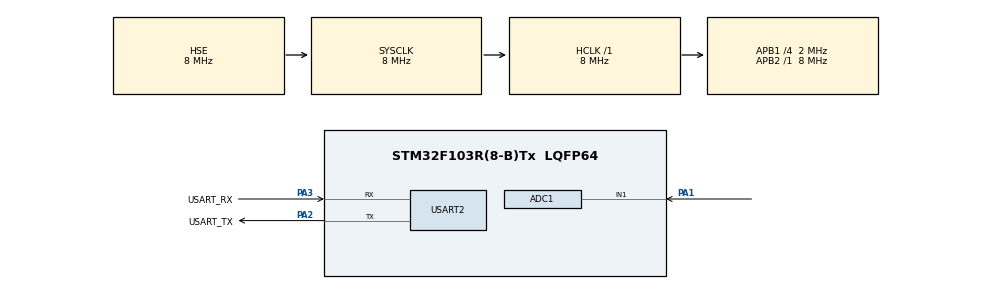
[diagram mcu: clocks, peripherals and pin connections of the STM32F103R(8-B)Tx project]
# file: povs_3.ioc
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ADC1.Channel-0\#ChannelRegularConversion=ADC_CHANNEL_1
ADC1.ContinuousConvMode=ENABLE
ADC1.NbrOfConversion=1
ADC1.NbrOfConversionFlag=1
ADC1.Rank-0\#ChannelRegularConversion=1
ADC1.SamplingTime-0\#ChannelRegularConversion=ADC_SAMPLETIME_239CYCLES_5
ADC1.master=1
Dma.ADC1.0.Direction=DMA_PERIPH_TO_MEMORY
Dma.ADC1.0.Instance=DMA1_Channel1
Dma.ADC1.0.MemDataAlignment=DMA_MDATAALIGN_WORD
Dma.ADC1.0.MemInc=DMA_MINC_ENABLE
Dma.ADC1.0.Mode=DMA_CIRCULAR
Dma.ADC1.0.PeriphDataAlignment=DMA_PDATAALIGN_WORD
Dma.ADC1.0.PeriphInc=DMA_PINC_DISABLE
Dma.ADC1.0.Priority=DMA_PRIORITY_LOW
Dma.Request0=ADC1
Mcu.Family=STM32F1
Mcu.Name=STM32F103R(8-B)Tx
Mcu.Package=LQFP64
NVIC.DMA1_Channel1_IRQn=true\:0\:0\:false\:false\:true\:false\:true\:true
NVIC.PriorityGroup=NVIC_PRIORITYGROUP_4
NVIC.TIM3_IRQn=true\:0\:0\:false\:false\:true\:true\:true\:true
NVIC.USART2_IRQn=true\:0\:0\:false\:false\:true\:true\:true\:true
PA1.Signal=ADCx_IN1
PA13.GPIO_Label=TMS
PA13.Mode=Serial_Wire
PA13.Signal=SYS_JTMS-SWDIO
PA14.GPIO_Label=TCK
PA14.Mode=Serial_Wire
PA14.Signal=SYS_JTCK-SWCLK
PA2.GPIO_Label=USART_TX
PA2.GPIO_Mode=GPIO_MODE_AF_PP
PA2.GPIO_PuPd=GPIO_NOPULL
PA2.GPIO_Speed=GPIO_SPEED_FREQ_LOW
PA2.Mode=Asynchronous
PA2.Signal=USART2_TX
PA3.GPIO_Label=USART_RX
PA3.GPIO_Mode=GPIO_MODE_AF_PP
PA3.GPIO_PuPd=GPIO_NOPULL
PA3.GPIO_Speed=GPIO_SPEED_FREQ_LOW
PA3.Mode=Asynchronous
PA3.Signal=USART2_RX
PB3.GPIO_Label=SWO
PB3.Signal=SYS_JTDO-TRACESWO
PC14-OSC32_IN.Mode=LSE-External-Oscillator
PC14-OSC32_IN.Signal=RCC_OSC32_IN
PC15-OSC32_OUT.Mode=LSE-External-Oscillator
PC15-OSC32_OUT.Signal=RCC_OSC32_OUT
PD0-OSC_IN.Mode=HSE-External-Clock-Source
PD0-OSC_IN.Signal=RCC_OSC_IN
PD1-OSC_OUT.Mode=HSE-External-Clock-Source
PD1-OSC_OUT.Signal=RCC_OSC_OUT
ProjectManager.HeapSize=0x200
ProjectManager.StackSize=0x400
ProjectManager.TargetToolchain=MDK-ARM V5
RCC.AHBFreq_Value=8000000
RCC.APB1CLKDivider=RCC_HCLK_DIV4
RCC.APB1Freq_Value=2000000
RCC.APB1TimFreq_Value=4000000
RCC.APB2Freq_Value=8000000
RCC.APB2TimFreq_Value=8000000
RCC.EnbaleCSS=true
RCC.HCLKFreq_Value=8000000
RCC.PLLMUL=RCC_PLL_MUL16
RCC.RTCClockSelection=RCC_RTCCLKSOURCE_LSE
RCC.SYSCLKFreq_VALUE=8000000
RCC.SYSCLKSource=RCC_SYSCLKSOURCE_HSE
RCC.USBFreq_Value=64000000
SH.ADCx_IN1.0=ADC1_IN1,IN1
TIM3.Period=1000-1
TIM3.Prescaler=4-1
USART2.VirtualMode=VM_ASYNC
VP_TIM3_VS_ClockSourceINT.Mode=Internal
board=NUCLEO-F103RB

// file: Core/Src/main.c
/* USER CODE BEGIN Header */
/**
  ******************************************************************************
  * @file           : main.c
  * @brief          : Main program body
  ******************************************************************************
  * @attention
  *
  * Copyright (c) 2023 STMicroelectronics.
  * All rights reserved.
  *
  * This software is licensed under terms that can be found in the LICENSE file
  * in the root directory of this software component.
  * If no LICENSE file comes with this software, it is provided AS-IS.
  *
  ******************************************************************************
  */
/* USER CODE END Header */
#include "main.h"
#include "adc.h"
#include "dma.h"
#include "tim.h"
#include "usart.h"
#include "gpio.h"

/* USER CODE BEGIN Includes */
#include <string.h>
#include <stdio.h>
#include <stdlib.h>
#include <math.h>

/* USER CODE END Includes */

/* USER CODE BEGIN PD */

const uint8_t UPDATE_RATE = 50; // Hz

/* USER CODE END PD */

/* USER CODE BEGIN PV */

uint32_t AnalogBuffer[1];
uint8_t bufferTextIn[16];
char command[16];

uint32_t frequency = 1; // 1Hz
uint32_t amplitude = 500;
float currentPhase = 0;

uint8_t sendLight = 1;

/* USER CODE END PV */

void SystemClock_Config(void);

/* USER CODE BEGIN 0 */

void Print(char *str)
{
  HAL_UART_Transmit(&huart2, (uint8_t *)str, strlen(str), HAL_MAX_DELAY);
}

void PrintLn(char *str)
{
  Print(str);
  Print("\r\n");
}

int8_t ConvertToProcessedValue(uint32_t rawValue, uint32_t min, uint32_t max, uint32_t center, uint32_t deadzone)
{
  if (rawValue < min) {
    rawValue = min;
  }
  if (rawValue > max) {
    rawValue = max;
  }

  const uint32_t lowCenter = center - deadzone;
  if (rawValue < lowCenter) {
    return -1 * (int8_t)(100 * (lowCenter - rawValue) / (lowCenter - min));
  }

  const uint32_t highCenter = center + deadzone;
  if (rawValue > highCenter) {
    return (int8_t)(100 * (rawValue - highCenter) / (max - highCenter));
  }
  return 0;
}

void PrintAnalogValue()
{
  char str[24];
  // print processed values as well as raw
  sprintf(str, "An: %4u", AnalogBuffer[0]);
  PrintLn(str);
}

void PrintWaveValue()
{
  int32_t waveValue = amplitude * sin(currentPhase);
  currentPhase += 2 * 3.14159265359 * frequency / UPDATE_RATE;
  if (currentPhase > 2 * 3.14159265359) {
    currentPhase -= 2 * 3.14159265359;
  }

  char str[24];
  sprintf(str, "An: %d", waveValue);
  PrintLn(str);
}

// should be called 1000Hz
void HandleTim3Interrupt() {
  static uint32_t callNum = 0;
  callNum++;
  if (callNum == 1000) { // 1Hz
    callNum = 0;
  }

  if (callNum % (1000 / UPDATE_RATE) == 0) {
    if (sendLight == 1) {
      PrintAnalogValue();
    } else {
      PrintWaveValue();
    }
  }
}

void PrintErrorState()
{
  char str[64];
  sprintf(str, "Error: %d", HAL_ERROR);
  PrintLn(str);
}

void ExecCommand(char *command)
{
  // if starts with frq: set frequency
  if (strncmp(command, "frq:", 4) == 0) {
    frequency = atoi(command + 5);
  } else if (strncmp(command, "amp:", 4) == 0) {
    amplitude = atoi(command + 5);
  } else if (strncmp(command, "light", 5) == 0) {
    sendLight = 1;
  } else if (strncmp(command, "sine", 4) == 0) {
    sendLight = 0;
  } else
  {
    PrintLn("Unknown command");
  }
}

void HAL_UART_RxCpltCallback(UART_HandleTypeDef *huart)
{
  if (huart == &huart2) {
    if (bufferTextIn[0] == '\n' || bufferTextIn[0] == '\r') {
      ExecCommand(command);

      memset(command, 0, sizeof(command));
    } else {
      strncat(command, (char *) bufferTextIn, 1);
    }

    if (strlen(command) >= sizeof(command) - 1) {
      PrintLn("Command too long");
      memset(command, 0, sizeof(command));
    }

    HAL_UART_Receive_IT(&huart2, bufferTextIn, 1);
  }
}

/* USER CODE END 0 */

int main(void)
{

  /* MCU Configuration--------------------------------------------------------*/

  /* Reset of all peripherals, Initializes the Flash interface and the Systick. */
  HAL_Init();

  /* Configure the system clock */
  SystemClock_Config();

  /* Initialize all configured peripherals */
  MX_GPIO_Init();
  MX_DMA_Init();
  MX_USART2_UART_Init();
  MX_TIM3_Init();
  MX_ADC1_Init();
  /* USER CODE BEGIN 2 */
  HAL_TIM_Base_Start_IT(&htim3);
  HAL_ADC_Start_DMA(&hadc1, AnalogBuffer, 2);
  HAL_UART_Receive_IT(&huart2, bufferTextIn, 1);

  /* USER CODE END 2 */

  /* Infinite loop */
  while (1)
  {

  }
}

void SystemClock_Config(void)
{
  RCC_OscInitTypeDef RCC_OscInitStruct = {0};
  RCC_ClkInitTypeDef RCC_ClkInitStruct = {0};
  RCC_PeriphCLKInitTypeDef PeriphClkInit = {0};

  /** Initializes the RCC Oscillators according to the specified parameters
  * in the RCC_OscInitTypeDef structure.
  */
  RCC_OscInitStruct.OscillatorType = RCC_OSCILLATORTYPE_HSE;
  RCC_OscInitStruct.HSEState = RCC_HSE_BYPASS;
  RCC_OscInitStruct.PLL.PLLState = RCC_PLL_NONE;
  if (HAL_RCC_OscConfig(&RCC_OscInitStruct) != HAL_OK)
  {
    Error_Handler();
  }

  /** Initializes the CPU, AHB and APB buses clocks
  */
  RCC_ClkInitStruct.ClockType = RCC_CLOCKTYPE_HCLK|RCC_CLOCKTYPE_SYSCLK
                              |RCC_CLOCKTYPE_PCLK1|RCC_CLOCKTYPE_PCLK2;
  RCC_ClkInitStruct.SYSCLKSource = RCC_SYSCLKSOURCE_HSE;
  RCC_ClkInitStruct.AHBCLKDivider = RCC_SYSCLK_DIV1;
  RCC_ClkInitStruct.APB1CLKDivider = RCC_HCLK_DIV4;
  RCC_ClkInitStruct.APB2CLKDivider = RCC_HCLK_DIV1;

  if (HAL_RCC_ClockConfig(&RCC_ClkInitStruct, FLASH_LATENCY_0) != HAL_OK)
  {
    Error_Handler();
  }
  PeriphClkInit.PeriphClockSelection = RCC_PERIPHCLK_ADC;
  PeriphClkInit.AdcClockSelection = RCC_ADCPCLK2_DIV2;
  if (HAL_RCCEx_PeriphCLKConfig(&PeriphClkInit) != HAL_OK)
  {
    Error_Handler();
  }

  /** Enables the Clock Security System
  */
  HAL_RCC_EnableCSS();
}

void Error_Handler(void)
{
  /* USER CODE BEGIN Error_Handler_Debug */
  /* User can add his own implementation to report the HAL error return state */
  __disable_irq();

  PrintErrorState();
  while (1)
  {
  }
  /* USER CODE END Error_Handler_Debug */
}
